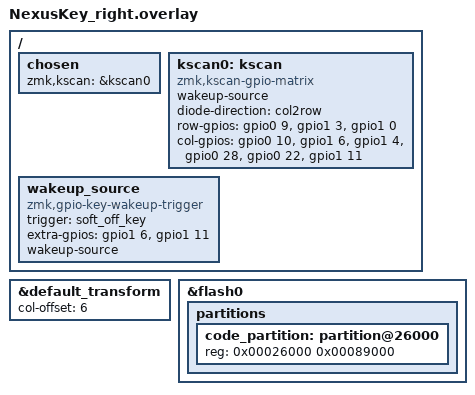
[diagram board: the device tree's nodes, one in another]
#include "NexusKey.dtsi"

/ {
    chosen {
        zmk,kscan = &kscan0;
    };

    kscan0: kscan {
        compatible = "zmk,kscan-gpio-matrix";
        wakeup-source;  // For Deep Sleep

        diode-direction = "col2row";

        row-gpios
            = <&gpio0 9 (GPIO_ACTIVE_HIGH | GPIO_PULL_DOWN)>    // P0.09
            , <&gpio1 3 (GPIO_ACTIVE_HIGH | GPIO_PULL_DOWN)>    // P1.03
            , <&gpio1 0 (GPIO_ACTIVE_HIGH | GPIO_PULL_DOWN)>    // P1.00
            ;

        col-gpios
            = <&gpio0 10 GPIO_ACTIVE_HIGH>  // P0.10
            , <&gpio1 6 GPIO_ACTIVE_HIGH>   // P1.06
            , <&gpio1 4 GPIO_ACTIVE_HIGH>   // P1.04
            , <&gpio0 28 GPIO_ACTIVE_HIGH>  // P0.28
            , <&gpio0 22 GPIO_ACTIVE_HIGH>  // P0.22
            , <&gpio1 11 GPIO_ACTIVE_HIGH>  // P1.11
            ;
    };
};

// Soft Off Behavior

/ {
    // Attach the keys device to wake up sources so it can turn on the keyboard.

    wakeup_source: wakeup_source {
        compatible = "zmk,gpio-key-wakeup-trigger";
        trigger = <&soft_off_key>;
        extra-gpios
        = <&gpio1 6 (GPIO_ACTIVE_HIGH | GPIO_PULL_UP)>
        , <&gpio1 11 (GPIO_ACTIVE_HIGH | GPIO_PULL_UP)>
        ;
        wakeup-source;
    };
};

// The keyboard's switch matrix is read from left to right, top to bottom.

&default_transform
{
    col-offset = <6>;
};

// code_partition shrink by half because of physical damage in right side.

&flash0 {
    /*
     * For more information, see:
     * http://docs.zephyrproject.org/latest/devices/dts/flash_partitions.html
     */
    partitions {
        code_partition: partition@26000 {
            reg = <0x00026000 0x00089000>;
        };
    };
};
